AUTOSAR XML (schema 00046)
package /ComponentTypes
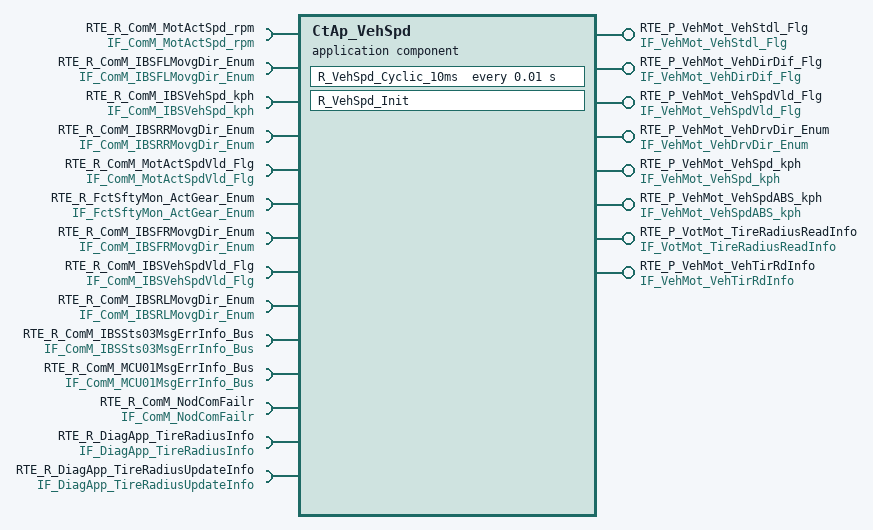
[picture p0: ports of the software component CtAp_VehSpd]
  application sw component type CtAp_VehSpd
    require port RTE_R_ComM_MotActSpd_rpm: nonqueued-receiver-com-spec{data-element=tec_ComM_MotActSpd_rpm, filter=data-filter-type=ALWAYS, init-value=0}, required-interface=IF_ComM_MotActSpd_rpm
    provide port RTE_P_VehMot_VehStdl_Flg: nonqueued-sender-com-spec{data-element=tec_VehMot_VehStdl_Flg, init-value=0}, provided-interface=IF_VehMot_VehStdl_Flg
    5 x require port:
      RTE_R_ComM_IBSFLMovgDir_Enum: nonqueued-receiver-com-spec{data-element=tec_ComM_IBSFLMovgDir_Enum, filter=data-filter-type=ALWAYS, init-value=0}, required-interface=IF_ComM_IBSFLMovgDir_Enum
      RTE_R_ComM_IBSVehSpd_kph: nonqueued-receiver-com-spec{data-element=tec_ComM_IBSVehSpd_kph, filter=data-filter-type=ALWAYS, init-value=0}, required-interface=IF_ComM_IBSVehSpd_kph
      RTE_R_ComM_IBSRRMovgDir_Enum: nonqueued-receiver-com-spec{data-element=tec_ComM_IBSRRMovgDir_Enum, filter=data-filter-type=ALWAYS, init-value=0}, required-interface=IF_ComM_IBSRRMovgDir_Enum
      RTE_R_ComM_MotActSpdVld_Flg: nonqueued-receiver-com-spec{data-element=tec_ComM_MotActSpdVld_Flg, filter=data-filter-type=ALWAYS, init-value=0}, required-interface=IF_ComM_MotActSpdVld_Flg
      RTE_R_FctSftyMon_ActGear_Enum: nonqueued-receiver-com-spec{data-element=tec_FctSftyMon_ActGear_Enum, filter=data-filter-type=ALWAYS, init-value=0}, required-interface=IF_FctSftyMon_ActGear_Enum
    provide port RTE_P_VehMot_VehDirDif_Flg: nonqueued-sender-com-spec{data-element=tec_VehMot_VehDirDif_Flg, init-value=0}, provided-interface=IF_VehMot_VehDirDif_Flg
    require port RTE_R_ComM_IBSFRMovgDir_Enum: nonqueued-receiver-com-spec{data-element=tec_ComM_IBSFRMovgDir_Enum, filter=data-filter-type=ALWAYS, init-value=0}, required-interface=IF_ComM_IBSFRMovgDir_Enum
    provide port RTE_P_VehMot_VehSpdVld_Flg: nonqueued-sender-com-spec{data-element=tec_VehMot_VehSpdVld_Flg, init-value=0}, provided-interface=IF_VehMot_VehSpdVld_Flg
    require port RTE_R_ComM_IBSVehSpdVld_Flg: nonqueued-receiver-com-spec{data-element=tec_ComM_IBSVehSpdVld_Flg, filter=data-filter-type=ALWAYS, init-value=0}, required-interface=IF_ComM_IBSVehSpdVld_Flg
    require port RTE_R_ComM_IBSRLMovgDir_Enum: nonqueued-receiver-com-spec{data-element=tec_ComM_IBSRLMovgDir_Enum, filter=data-filter-type=ALWAYS, init-value=0}, required-interface=IF_ComM_IBSRLMovgDir_Enum
    provide port RTE_P_VehMot_VehDrvDir_Enum: nonqueued-sender-com-spec{data-element=tec_VehMot_VehDrvDir_Enum, init-value=0}, provided-interface=IF_VehMot_VehDrvDir_Enum
    require port RTE_R_ComM_IBSSts03MsgErrInfo_Bus: required-interface=IF_ComM_IBSSts03MsgErrInfo_Bus
      required-com-specs:
        data-element=tec_ComM_IBSSts03CRCInfo_Bus, filter=data-filter-type=ALWAYS, init-value=fields=[ComM_MonStatIBSSts03CRCErrorInfo:0, ComM_MonResIBSSts03CRCErrorInfo:0, ComM_ErrStatIBSSts03CRCErrorInfo:0, ComM_ErrResIBSSts03CRCErrorInfo:0]
        data-element=tec_ComM_IBSSts03CRCDTCInfo_Bus, filter=data-filter-type=ALWAYS, init-value=fields=[ComM_MonStatIBSSts03CRCDTCErrorInfo:0, ComM_MonResIBSSts03CRCDTCErrorInfo:0, ComM_ErrStatIBSSts03CRCDTCErrorInfo:0, ComM_ErrResIBSSts03CRCDTCErrorInfo:0]
        data-element=tec_ComM_IBSSts03TimeoutDTCInfo_Bus, filter=data-filter-type=ALWAYS, init-value=fields=[ComM_MonStatIBSSts03TimeoutDTCErrorInfo:0, ComM_MonResIBSSts03TimeoutDTCErrorInfo:0, ComM_ErrStatIBSSts03TimeoutDTCErrorInfo:0, ComM_ErrResIBSSts03TimeoutDTCErrorInfo:0]
        data-element=tec_ComM_IBSSts03E2ETimeoutInfo_Bus, filter=data-filter-type=ALWAYS, init-value=fields=[ComM_MonStatIBSSts03E2ETimeoutInfo:0, ComM_MonResIBSSts03E2ETimeoutInfo:0, ComM_ErrStatIBSSts03E2ETimeoutInfo:0, ComM_ErrResIBSSts03E2ETimeoutInfo:0]
    require port RTE_R_ComM_MCU01MsgErrInfo_Bus: required-interface=IF_ComM_MCU01MsgErrInfo_Bus
      required-com-specs:
        data-element=tec_ComM_MCU01TimeoutInfo_Bus, filter=data-filter-type=ALWAYS, init-value=fields=[ComM_MonStatMCU01TimeoutInfo:0, ComM_MonResMCU01TimeoutInfo:0, ComM_ErrStatMCU01TimeoutInfo:0, ComM_ErrResMCU01TimeoutInfo:0]
        data-element=tec_ComM_MCU01CRCDTCInfo_Bus, filter=data-filter-type=ALWAYS, init-value=fields=[ComM_MonStatMCU01CRCDTCErrorInfo:0, ComM_MonResMCU01CRCDTCErrorInfo:0, ComM_ErrStatMCU01CRCDTCErrorInfo:0, ComM_ErrResMCU01CRCDTCErrorInfo:0]
        data-element=tec_ComM_MCU01CRCInfo_Bus, filter=data-filter-type=ALWAYS, init-value=fields=[ComM_MonStatMCU01CRCErrorInfo:0, ComM_MonResMCU01CRCErrorInfo:0, ComM_ErrStatMCU01CRCErrorInfo:0, ComM_ErrResMCU01CRCErrorInfo:0]
        data-element=tec_ComM_MCU01TimeoutDTCInfo_Bus, filter=data-filter-type=ALWAYS, init-value=fields=[ComM_MonStatMCU01TimeoutDTCErrorInfo:0, ComM_MonResMCU01TimeoutDTCErrorInfo:0, ComM_ErrStatMCU01TimeoutDTCErrorInfo:0, ComM_ErrResMCU01TimeoutDTCErrorInfo:0]
        data-element=tec_ComM_MCU01E2ETimeoutInfo_Bus, filter=data-filter-type=ALWAYS, init-value=fields=[ComM_MonStatMCU01E2ETimeoutInfo:0, ComM_MonResMCU01E2ETimeoutInfo:0, ComM_ErrStatMCU01E2ETimeoutInfo:0, ComM_ErrResMCU01E2ETimeoutInfo:0]
    provide port RTE_P_VehMot_VehSpd_kph: nonqueued-sender-com-spec{data-element=tec_VehMot_VehSpd_kph, init-value=0}, provided-interface=IF_VehMot_VehSpd_kph
    provide port RTE_P_VehMot_VehSpdABS_kph: nonqueued-sender-com-spec{data-element=tec_VehMot_VehSpdABS_kph, init-value=0}, provided-interface=IF_VehMot_VehSpdABS_kph
    require port RTE_R_ComM_NodComFailr: required-interface=IF_ComM_NodComFailr
      required-com-specs:
        data-element=tec_ComM_ACUNodComFailr_Flg, filter=data-filter-type=ALWAYS, init-value=0
        data-element=tec_ComM_SGWNodComFailr_Flg, filter=data-filter-type=ALWAYS, init-value=0
        data-element=tec_ComM_CGWNodComFailr_Flg, filter=data-filter-type=ALWAYS, init-value=0
        data-element=tec_ComM_TCUNodComFailr_Flg, filter=data-filter-type=ALWAYS, init-value=0
        data-element=tec_ComM_BCMNodComFailr_Flg, filter=data-filter-type=ALWAYS, init-value=0
        data-element=tec_ComM_PRNDNodComFailr_Flg, filter=data-filter-type=ALWAYS, init-value=0
        data-element=tec_ComM_IVINodComFailr_Flg, filter=data-filter-type=ALWAYS, init-value=0
        data-element=tec_ComM_DCDCNodComFailr_Flg, filter=data-filter-type=ALWAYS, init-value=0
        data-element=tec_ComM_OBCNodComFailr_Flg, filter=data-filter-type=ALWAYS, init-value=0
        data-element=tec_ComM_CHIBSNodComFailr_Flg, filter=data-filter-type=ALWAYS, init-value=0
        data-element=tec_ComM_MCUNodComFailr_Flg, filter=data-filter-type=ALWAYS, init-value=0
        data-element=tec_ComM_EVCOMNodComFailr_Flg, filter=data-filter-type=ALWAYS, init-value=0
        data-element=tec_ComM_EPTIBSNodComFailr_Flg, filter=data-filter-type=ALWAYS, init-value=0
        data-element=tec_ComM_DCMNodComFailr_Flg, filter=data-filter-type=ALWAYS, init-value=0
        data-element=tec_ComM_BMSNodComFailr_Flg, filter=data-filter-type=ALWAYS, init-value=0
        data-element=tec_ComM_APTCNodComFailr_Flg, filter=data-filter-type=ALWAYS, init-value=0
        data-element=tec_ComM_ADCUNodComFailr_Flg, filter=data-filter-type=ALWAYS, init-value=0
        data-element=tec_ComM_DCMRRNodComFailr_Flg, filter=data-filter-type=ALWAYS, init-value=0
        data-element=tec_ComM_DCMRLNodComFailr_Flg, filter=data-filter-type=ALWAYS, init-value=0
        data-element=tec_ComM_DCMFRNodComFailr_Flg, filter=data-filter-type=ALWAYS, init-value=0
        data-element=tec_ComM_DCMFLNodComFailr_Flg, filter=data-filter-type=ALWAYS, init-value=0
        data-element=tec_ComM_SGWCHNodComFailr_Flg, init-value=0
    provide port RTE_P_VotMot_TireRadiusReadInfo: nonqueued-sender-com-spec{data-element=tec_VotMot_TireRadiusReadInfo, init-value=0}, provided-interface=IF_VotMot_TireRadiusReadInfo
    require port RTE_R_DiagApp_TireRadiusInfo: nonqueued-receiver-com-spec{data-element=tec_DiagApp_TireRadiusInfo, filter=data-filter-type=ALWAYS, init-value=0}, required-interface=IF_DiagApp_TireRadiusInfo
    require port RTE_R_DiagApp_TireRadiusUpdateInfo: nonqueued-receiver-com-spec{data-element=tec_DiagApp_TireRadiusUpdateInfo, filter=data-filter-type=ALWAYS, init-value=0}, required-interface=IF_DiagApp_TireRadiusUpdateInfo
    provide port RTE_P_VehMot_VehTirRdInfo: nonqueued-sender-com-spec{data-element=tec_VehMot_VehTirRdInfo, init-value=0}, provided-interface=IF_VehMot_VehTirRdInfo
    behavior CtAp_VehSpd_InternalBehavior
      timing event TMT_R_VehSpd_Cyclic_10ms: start-on-event=R_VehSpd_Cyclic_10ms, period=0.01
      init event CtAp_VehSpd_InitEvent: start-on-event=R_VehSpd_Init
      runnable R_VehSpd_Cyclic_10ms
        data-receive-point-by-arguments:
          16 x access:
            REC_RTE_R_ComM_IBSFLMovgDir_Enum_tec_ComM_IBSFLMovgDir_Enum: accessed-variable=RTE_R_ComM_IBSFLMovgDir_Enum.tec_ComM_IBSFLMovgDir_Enum
            REC_RTE_R_ComM_IBSFRMovgDir_Enum_tec_ComM_IBSFRMovgDir_Enum: accessed-variable=RTE_R_ComM_IBSFRMovgDir_Enum.tec_ComM_IBSFRMovgDir_Enum
            REC_RTE_R_ComM_IBSRLMovgDir_Enum_tec_ComM_IBSRLMovgDir_Enum: accessed-variable=RTE_R_ComM_IBSRLMovgDir_Enum.tec_ComM_IBSRLMovgDir_Enum
            REC_RTE_R_ComM_IBSRRMovgDir_Enum_tec_ComM_IBSRRMovgDir_Enum: accessed-variable=RTE_R_ComM_IBSRRMovgDir_Enum.tec_ComM_IBSRRMovgDir_Enum
            REC_RTE_R_ComM_IBSSts03MsgErrInfo_Bus_tec_ComM_IBSSts03CRCInfo_Bus: accessed-variable=RTE_R_ComM_IBSSts03MsgErrInfo_Bus.tec_ComM_IBSSts03CRCInfo_Bus
            REC_RTE_R_ComM_IBSSts03MsgErrInfo_Bus_tec_ComM_IBSSts03E2ETimeoutInfo_Bus: accessed-variable=RTE_R_ComM_IBSSts03MsgErrInfo_Bus.tec_ComM_IBSSts03E2ETimeoutInfo_Bus
            REC_RTE_R_ComM_IBSVehSpdVld_Flg_tec_ComM_IBSVehSpdVld_Flg: accessed-variable=RTE_R_ComM_IBSVehSpdVld_Flg.tec_ComM_IBSVehSpdVld_Flg
            REC_RTE_R_ComM_IBSVehSpd_kph_tec_ComM_IBSVehSpd_kph: accessed-variable=RTE_R_ComM_IBSVehSpd_kph.tec_ComM_IBSVehSpd_kph
            REC_RTE_R_ComM_MCU01MsgErrInfo_Bus_tec_ComM_MCU01CRCInfo_Bus: accessed-variable=RTE_R_ComM_MCU01MsgErrInfo_Bus.tec_ComM_MCU01CRCInfo_Bus
            REC_RTE_R_ComM_MCU01MsgErrInfo_Bus_tec_ComM_MCU01E2ETimeoutInfo_Bus: accessed-variable=RTE_R_ComM_MCU01MsgErrInfo_Bus.tec_ComM_MCU01E2ETimeoutInfo_Bus
            REC_RTE_R_ComM_MotActSpdVld_Flg_tec_ComM_MotActSpdVld_Flg: accessed-variable=RTE_R_ComM_MotActSpdVld_Flg.tec_ComM_MotActSpdVld_Flg
            REC_RTE_R_ComM_MotActSpd_rpm_tec_ComM_MotActSpd_rpm: accessed-variable=RTE_R_ComM_MotActSpd_rpm.tec_ComM_MotActSpd_rpm
            REC_RTE_R_FctSftyMon_ActGear_Enum_tec_FctSftyMon_ActGear_Enum: accessed-variable=RTE_R_FctSftyMon_ActGear_Enum.tec_FctSftyMon_ActGear_Enum
            REC_RTE_R_ComM_NodComFailr_tec_ComM_MCUNodComFailr_Flg: accessed-variable=RTE_R_ComM_NodComFailr.tec_ComM_MCUNodComFailr_Flg
            REC_RTE_R_DiagApp_TireRadiusInfo_tec_DiagApp_TireRadiusInfo: accessed-variable=RTE_R_DiagApp_TireRadiusInfo.tec_DiagApp_TireRadiusInfo
            REC_RTE_R_DiagApp_TireRadiusUpdateInfo_tec_DiagApp_TireRadiusUpdateInfo: accessed-variable=RTE_R_DiagApp_TireRadiusUpdateInfo.tec_DiagApp_TireRadiusUpdateInfo
        data-send-points:
          8 x access:
            SEND_RTE_P_VehMot_VehDirDif_Flg_tec_VehMot_VehDirDif_Flg: accessed-variable=RTE_P_VehMot_VehDirDif_Flg.tec_VehMot_VehDirDif_Flg
            SEND_RTE_P_VehMot_VehDrvDir_Enum_tec_VehMot_VehDrvDir_Enum: accessed-variable=RTE_P_VehMot_VehDrvDir_Enum.tec_VehMot_VehDrvDir_Enum
            SEND_RTE_P_VehMot_VehSpdABS_kph_tec_VehMot_VehSpdABS_kph: accessed-variable=RTE_P_VehMot_VehSpdABS_kph.tec_VehMot_VehSpdABS_kph
            SEND_RTE_P_VehMot_VehSpdVld_Flg_tec_VehMot_VehSpdVld_Flg: accessed-variable=RTE_P_VehMot_VehSpdVld_Flg.tec_VehMot_VehSpdVld_Flg
            SEND_RTE_P_VehMot_VehSpd_kph_tec_VehMot_VehSpd_kph: accessed-variable=RTE_P_VehMot_VehSpd_kph.tec_VehMot_VehSpd_kph
            SEND_RTE_P_VehMot_VehStdl_Flg_tec_VehMot_VehStdl_Flg: accessed-variable=RTE_P_VehMot_VehStdl_Flg.tec_VehMot_VehStdl_Flg
            SEND_RTE_P_VotMot_TireRadiusReadInfo_tec_VotMot_TireRadiusReadInfo: accessed-variable=RTE_P_VotMot_TireRadiusReadInfo.tec_VotMot_TireRadiusReadInfo
            SEND_RTE_P_VehMot_VehTirRdInfo_tec_VehMot_VehTirRdInfo: accessed-variable=RTE_P_VehMot_VehTirRdInfo.tec_VehMot_VehTirRdInfo
      runnable R_VehSpd_Init
  swc implementation CtAp_VehSpd_Implementation: behavior=CtAp_VehSpd_InternalBehavior
